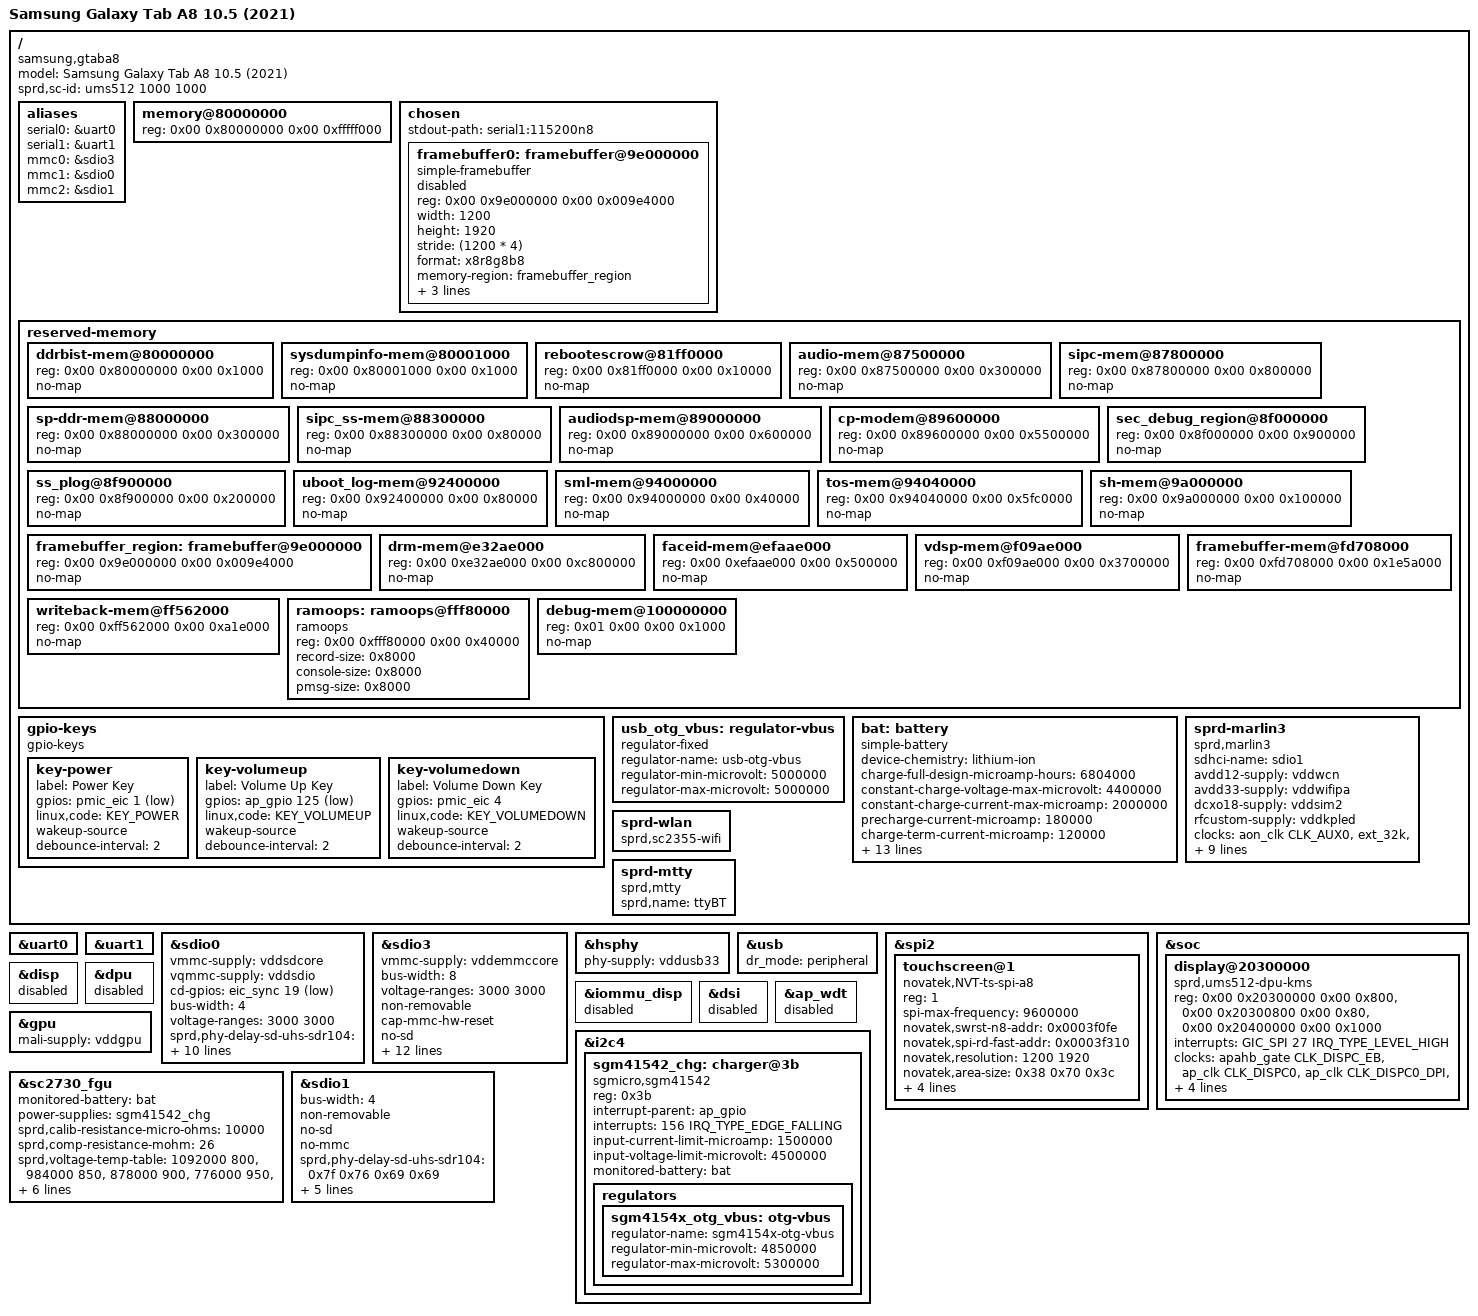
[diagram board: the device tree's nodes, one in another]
// SPDX-License-Identifier: (GPL-2.0 OR MIT)
/*
 * Samsung Galaxy Tab A8 10.5 (2021) - SM-X200 (Wi-Fi) / SM-X205 (LTE)
 * Unisoc UMS512 / Tiger T618 SoC
 *
 * Board Device Tree for Nura Edge / Mainline Linux
 */

/dts-v1/;

#include <dt-bindings/clock/sprd,ums512-clk.h>
#include <dt-bindings/gpio/gpio.h>
#include <dt-bindings/input/gpio-keys.h>
#include <dt-bindings/input/input.h>
#include <dt-bindings/interrupt-controller/arm-gic.h>
#include <dt-bindings/interrupt-controller/irq.h>
#include "ums512.dtsi"
#include "sc2730.dtsi"

/ {
	model = "Samsung Galaxy Tab A8 10.5 (2021)";
	compatible = "samsung,gtaba8", "sprd,ums512";

	/*
	 * Matches stock base DTB sprd,sc-id. Note: LK still selects DTBO by
	 * board_id 0x1100, so dtbo-noop.img must be flashed to the dtbo partition.
	 */
	sprd,sc-id = "ums512 1000 1000";

	aliases {
		serial0 = &uart0;
		serial1 = &uart1;
		mmc0 = &sdio3;
		mmc1 = &sdio0;
		mmc2 = &sdio1;
	};

	memory@80000000 {
		device_type = "memory";
		reg = <0x00 0x80000000 0x00 0xfffff000>;
	};

	chosen {
		#address-cells = <2>;
		#size-cells = <2>;
		ranges;
		stdout-path = "serial1:115200n8";

		framebuffer0: framebuffer@9e000000 {
			compatible = "simple-framebuffer";
			reg = <0x00 0x9e000000 0x00 0x009e4000>;
			width = <1200>;
			height = <1920>;
			stride = <(1200 * 4)>;
			format = "x8r8g8b8";
			memory-region = <&framebuffer_region>;
			clocks = <&apahb_gate CLK_DISPC_EB>,
				 <&ap_clk CLK_DISPC0>,
				 <&ap_clk CLK_DISPC0_DPI>,
				 <&apahb_gate CLK_DSI_EB>;
			/* ums512-dpu-kms owns the scanout; it reads this node's reg. */
			status = "disabled";
		};
	};

	reserved-memory {
		#address-cells = <2>;
		#size-cells = <2>;
		ranges;

		ddrbist-mem@80000000 {
			reg = <0x00 0x80000000 0x00 0x1000>;
			no-map;
		};

		sysdumpinfo-mem@80001000 {
			reg = <0x00 0x80001000 0x00 0x1000>;
			no-map;
		};

		rebootescrow@81ff0000 {
			reg = <0x00 0x81ff0000 0x00 0x10000>;
			no-map;
		};

		audio-mem@87500000 {
			reg = <0x00 0x87500000 0x00 0x300000>;
			no-map;
		};

		sipc-mem@87800000 {
			reg = <0x00 0x87800000 0x00 0x800000>;
			no-map;
		};

		sp-ddr-mem@88000000 {
			reg = <0x00 0x88000000 0x00 0x300000>;
			no-map;
		};

		sipc_ss-mem@88300000 {
			reg = <0x00 0x88300000 0x00 0x80000>;
			no-map;
		};

		audiodsp-mem@89000000 {
			reg = <0x00 0x89000000 0x00 0x600000>;
			no-map;
		};

		cp-modem@89600000 {
			reg = <0x00 0x89600000 0x00 0x5500000>;
			no-map;
		};

		sec_debug_region@8f000000 {
			reg = <0x00 0x8f000000 0x00 0x900000>;
			no-map;
		};

		ss_plog@8f900000 {
			reg = <0x00 0x8f900000 0x00 0x200000>;
			no-map;
		};

		uboot_log-mem@92400000 {
			reg = <0x00 0x92400000 0x00 0x80000>;
			no-map;
		};

		sml-mem@94000000 {
			reg = <0x00 0x94000000 0x00 0x40000>;
			no-map;
		};

		tos-mem@94040000 {
			reg = <0x00 0x94040000 0x00 0x5fc0000>;
			no-map;
		};

		sh-mem@9a000000 {
			reg = <0x00 0x9a000000 0x00 0x100000>;
			no-map;
		};

		/* Bootloader splash framebuffer at 0x9e000000 (1200x1920 @ 32bpp) */
		framebuffer_region: framebuffer@9e000000 {
			reg = <0x00 0x9e000000 0x00 0x009e4000>;
			no-map;
		};

		/*
		 * TrustZone-firewalled SVP/DRM, FaceID, VDSP, and display carveouts
		 * from stock live FDT. Must be no-map so buddy/CMA never allocate
		 * pages in firewalled DDR (non-secure writes are dropped / read 0).
		 */
		drm-mem@e32ae000 {
			reg = <0x00 0xe32ae000 0x00 0xc800000>;
			no-map;
		};

		faceid-mem@efaae000 {
			reg = <0x00 0xefaae000 0x00 0x500000>;
			no-map;
		};

		vdsp-mem@f09ae000 {
			reg = <0x00 0xf09ae000 0x00 0x3700000>;
			no-map;
		};

		framebuffer-mem@fd708000 {
			reg = <0x00 0xfd708000 0x00 0x1e5a000>;
			no-map;
		};

		writeback-mem@ff562000 {
			reg = <0x00 0xff562000 0x00 0xa1e000>;
			no-map;
		};

		/* Ramoops / pstore persistent crash log buffer matching recovery FDT */
		ramoops: ramoops@fff80000 {
			compatible = "ramoops";
			reg = <0x00 0xfff80000 0x00 0x40000>;
			record-size = <0x8000>;
			console-size = <0x8000>;
			pmsg-size = <0x8000>;
		};

		debug-mem@100000000 {
			reg = <0x01 0x00 0x00 0x1000>;
			no-map;
		};
	};

	gpio-keys {
		compatible = "gpio-keys";

		key-power {
			label = "Power Key";
			gpios = <&pmic_eic 1 GPIO_ACTIVE_LOW>;
			linux,code = <KEY_POWER>;
			wakeup-source;
			debounce-interval = <2>;
		};

		key-volumeup {
			label = "Volume Up Key";
			gpios = <&ap_gpio 125 GPIO_ACTIVE_LOW>;
			linux,code = <KEY_VOLUMEUP>;
			wakeup-source;
			debounce-interval = <2>;
		};

		key-volumedown {
			label = "Volume Down Key";
			gpios = <&pmic_eic 4 GPIO_ACTIVE_HIGH>;
			linux,code = <KEY_VOLUMEDOWN>;
			wakeup-source;
			debounce-interval = <2>;
		};
	};

	usb_otg_vbus: regulator-vbus {
		compatible = "regulator-fixed";
		regulator-name = "usb-otg-vbus";
		regulator-min-microvolt = <5000000>;
		regulator-max-microvolt = <5000000>;
	};

	bat: battery {
		compatible = "simple-battery";
		device-chemistry = "lithium-ion";
		charge-full-design-microamp-hours = <6804000>;
		constant-charge-voltage-max-microvolt = <4400000>;
		constant-charge-current-max-microamp = <2000000>;
		precharge-current-microamp = <180000>;
		charge-term-current-microamp = <120000>;
		voltage-min-design-microvolt = <3456000>;
		factory-internal-resistance-micro-ohms = <120000>;
		operating-range-celsius = <0 50>;
		ocv-capacity-celsius = <20>;
		ocv-capacity-table-0 =
			<4354000 100>, <4293000 95>, <4236000 90>, <4180000 85>,
			<4126000 80>,  <4075000 75>, <4027000 70>, <3985000 65>,
			<3942000 60>,  <3887000 55>, <3854000 50>, <3830000 45>,
			<3811000 40>,  <3796000 35>, <3782000 30>, <3765000 25>,
			<3746000 20>,  <3722000 15>, <3693000 10>, <3681000 5>,
			<3400000 0>;
		resistance-temp-table =
			<45 88>, <25 100>, <10 156>, <0 541>, <(-10) 683>, <(-20) 756>;
	};

	sprd-marlin3 {
		compatible = "sprd,marlin3";
		sdhci-name = <&sdio1>;
		avdd12-supply = <&vddwcn>;
		avdd33-supply = <&vddwifipa>;
		dcxo18-supply = <&vddsim2>;
		rfcustom-supply = <&vddkpled>;
		clocks = <&aon_clk CLK_AUX0>, <&ext_32k>, <&aonapb_gate CLK_AUX0_EB>;
		clock-names = "clk_32k", "source", "enable";
		xtal-26m-clk-type = "TSX";
		enable-gpios = <&ap_gpio 143 GPIO_ACTIVE_HIGH>;
		reset-gpios = <&ap_gpio 95 GPIO_ACTIVE_HIGH>;
		m2-to-ap-irq-gpios = <&ap_gpio 94 GPIO_ACTIVE_HIGH>;
		m2-wakeup-ap-gpios = <&ap_gpio 32 GPIO_ACTIVE_HIGH>;
		permit-ap-send-gpios = <&ap_gpio 121 GPIO_ACTIVE_HIGH>;
		m2-to-ap-coexist-gpios = <&ap_gpio 119 GPIO_ACTIVE_HIGH>;
		/* Use external GPIO RX IRQ (m2-wakeup-ap) + SDMA packet mode on sdhci-r11. */
		blksz-512;
	};

	sprd-wlan {
		compatible = "sprd,sc2355-wifi";
	};

	sprd-mtty {
		compatible = "sprd,mtty";
		sprd,name = "ttyBT";
	};
};

&uart0 {
	status = "okay";
};

&uart1 {
	status = "okay";
};

/* MicroSD Card */
&sdio0 {
	status = "okay";
	vmmc-supply = <&vddsdcore>;
	vqmmc-supply = <&vddsdio>;
	cd-gpios = <&eic_sync 19 GPIO_ACTIVE_LOW>;
	bus-width = <4>;
	voltage-ranges = <3000 3000>;
	sprd,phy-delay-sd-uhs-sdr104 = <0x7f 0x73 0x72 0x72>;
	sprd,phy-delay-sd-uhs-sdr50 = <0x6e 0x7f 0x01 0x01>;
	sprd,phy-delay-sd-highspeed = <0x7f 0x53 0xc4 0xc4>;
	sprd,phy-delay-legacy = <0x7f 0x1a 0x9a 0x9a>;
	sd-uhs-sdr104;
	sd-uhs-sdr50;
	no-sdio;
	no-mmc;
};

/* Internal eMMC (boot device) */
&sdio3 {
	status = "okay";
	vmmc-supply = <&vddemmccore>;
	bus-width = <8>;
	voltage-ranges = <3000 3000>;
	non-removable;
	cap-mmc-hw-reset;
	no-sd;
	no-sdio;
	mmc-hs400-enhanced-strobe;
	mmc-hs400-1_8v;
	mmc-hs200-1_8v;
	mmc-ddr-1_8v;
	sprd,phy-delay-mmc-hs400es = <0x40 0x7f 0x2d 0x2d>;
	sprd,phy-delay-mmc-hs400 = <0x3f 0xdf 0x2f 0x2f>;
	sprd,phy-delay-mmc-hs200 = <0x7f 0xde 0xd4 0xd4>;
	sprd,phy-delay-mmc-ddr52 = <0x3e 0x37 0x24 0x24>;
	sprd,phy-delay-mmc-highspeed = <0x60 0x30 0x30 0x30>;
};

/* USB2 PHY & MUSB peripheral mode for ConfigFS RNDIS + ACM */
&hsphy {
	status = "okay";
	phy-supply = <&vddusb33>;
};

&usb {
	status = "okay";
	dr_mode = "peripheral";
};

/* Novatek NT36523B TDDI Touchscreen on SPI2 (0x70a00000 CS 1) */
&spi2 {
	status = "okay";

	touchscreen@1 {
		compatible = "novatek,NVT-ts-spi-a8";
		reg = <1>;
		spi-max-frequency = <9600000>;
		novatek,swrst-n8-addr = <0x0003f0fe>;
		novatek,spi-rd-fast-addr = <0x0003f310>;
		novatek,resolution = <1200 1920>;
		novatek,area-size = <0x38 0x70 0x3c>;
		novatek,max_touch_num = <10>;
		novatek,reset-gpio = <&ap_gpio 145 GPIO_ACTIVE_HIGH>;
		novatek,irq-gpio = <&eic_async 0 IRQ_TYPE_EDGE_RISING>;
		novatek,fw_name = "nt36523b_qc_inx_fw.bin";
	};
};

/*
 * Native KMS on UMS512 DPU r4p0: adopts the bootloader-initialised MIPI-DSI
 * video link (works across all SM-X200 panel vendors) and owns the 4-plane
 * hardware DPU layer engine, VSYNC/page-flip IRQs, and CMA DMA scanout.
 */
&soc {
	display@20300000 {
		compatible = "sprd,ums512-dpu-kms";
		reg = <0x00 0x20300000 0x00 0x800>,
		      <0x00 0x20300800 0x00 0x80>,
		      <0x00 0x20400000 0x00 0x1000>;
		interrupts = <GIC_SPI 27 IRQ_TYPE_LEVEL_HIGH>;
		clocks = <&apahb_gate CLK_DISPC_EB>,
			 <&ap_clk CLK_DISPC0>,
			 <&ap_clk CLK_DISPC0_DPI>,
			 <&apahb_gate CLK_DSI_EB>;
		clock-names = "core", "clk", "dpi", "dsi";
		width-mm = <136>;
		height-mm = <225>;
		sprd,boot-framebuffer = <&framebuffer0>;
	};
};

/* Disabled so display@20300000 (ums512-dpu-kms) owns the DPU & VAU IOMMU */
&disp {
	status = "disabled";
};

&dpu {
	status = "disabled";
};

&iommu_disp {
	status = "disabled";
};

&dsi {
	status = "disabled";
};

/* Mali-G52 MP2 Bifrost GPU (Panfrost) */
&gpu {
	status = "okay";
	mali-supply = <&vddgpu>;
};

/* Bring-up: AP watchdog off (PMIC sc27xx_wdt handles bootloader-armed watchdog) */
&ap_wdt {
	status = "disabled";
};

/* SGM41542 Switching Charger on I2C4 (0x70700000, addr 0x3b) */
&i2c4 {
	status = "okay";

	sgm41542_chg: charger@3b {
		compatible = "sgmicro,sgm41542";
		reg = <0x3b>;
		interrupt-parent = <&ap_gpio>;
		interrupts = <156 IRQ_TYPE_EDGE_FALLING>;
		input-current-limit-microamp = <1500000>;
		input-voltage-limit-microvolt = <4500000>;
		monitored-battery = <&bat>;

		regulators {
			sgm4154x_otg_vbus: otg-vbus {
				regulator-name = "sgm4154x-otg-vbus";
				regulator-min-microvolt = <4850000>;
				regulator-max-microvolt = <5300000>;
			};
		};
	};
};

/* SC2730 PMIC Fuel Gauge Unit */
&sc2730_fgu {
	status = "okay";
	monitored-battery = <&bat>;
	power-supplies = <&sgm41542_chg>;
	sprd,calib-resistance-micro-ohms = <10000>;
	sprd,comp-resistance-mohm = <26>;
	sprd,voltage-temp-table =
		<1092000 800>,  <984000 850>,  <878000 900>,  <776000 950>,
		<679000 1000>,  <591000 1050>, <511000 1100>, <441000 1150>,
		<379000 1200>,  <325000 1250>, <278000 1300>, <238000 1350>,
		<204000 1400>,  <175000 1450>, <150000 1500>, <129000 1550>,
		<112000 1600>,  <97000 1650>,  <84000 1700>,  <73000 1750>,
		<63000 1800>,   <55000 1850>;
};

/* WCN Marlin3-Lite SDIO1 Interface (0x71200000) */
&sdio1 {
	bus-width = <4>;
	non-removable;
	no-sd;
	no-mmc;
	sprd,phy-delay-sd-uhs-sdr104 = <0x7f 0x76 0x69 0x69>;
	sprd,phy-delay-sd-uhs-sdr50 = <0x7f 0xf7 0xf5 0xf5>;
	sd-uhs-sdr50;
	sd-uhs-sdr104;
	keep-power-in-suspend;
	status = "okay";
};
